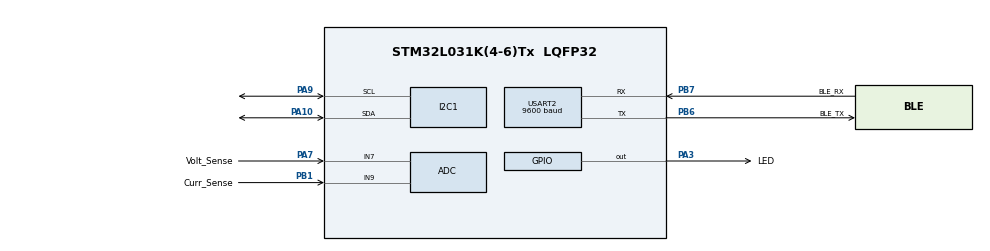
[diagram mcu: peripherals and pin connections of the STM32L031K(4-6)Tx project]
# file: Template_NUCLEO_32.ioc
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ADC.ExternalTrigConv=ADC_SOFTWARE_START
ADC.OversamplingMode=DISABLE
I2C1.Timing=0x00707CBB
Mcu.Family=STM32L0
Mcu.Name=STM32L031K(4-6)Tx
Mcu.Package=LQFP32
NVIC.TIM2_IRQn=true\:0\:0\:false\:false\:true\:true\:true
NVIC.USART2_IRQn=true\:0\:0\:false\:false\:true\:true\:true
PA10.Mode=I2C
PA10.Signal=I2C1_SDA
PA13.GPIO_Label=TMS
PA13.Mode=Serial_Wire
PA13.Signal=SYS_SWDIO
PA14.GPIO_Label=TCK
PA14.Mode=Serial_Wire
PA14.Signal=SYS_SWCLK
PA3.GPIO_Label=LED
PA3.Signal=GPIO_Output
PA7.GPIO_Label=Volt_Sense
PA7.Signal=SharedAnalog_PA7
PA9.Mode=I2C
PA9.Signal=I2C1_SCL
PB1.GPIO_Label=Curr_Sense
PB1.Signal=SharedAnalog_PB1
PB6.GPIO_Label=BLE_TX
PB6.Mode=Asynchronous
PB6.Signal=USART2_TX
PB7.GPIO_Label=BLE_RX
PB7.Mode=Asynchronous
PB7.Signal=USART2_RX
PC14-OSC32_IN.Mode=LSE-External-Oscillator
PC14-OSC32_IN.Signal=RCC_OSC32_IN
PC15-OSC32_OUT.Mode=LSE-External-Oscillator
PC15-OSC32_OUT.Signal=RCC_OSC32_OUT
ProjectManager.HeapSize=0x200
ProjectManager.StackSize=0x400
ProjectManager.TargetToolchain=MDK-ARM V5.27
RCC.AHBFreq_Value=32000000
RCC.APB1Freq_Value=32000000
RCC.APB1TimFreq_Value=32000000
RCC.APB2Freq_Value=32000000
RCC.APB2TimFreq_Value=32000000
RCC.HCLKFreq_Value=32000000
RCC.HSE_VALUE=8000000
RCC.HSI16_VALUE=16000000
RCC.HSI48_VALUE=48000000
RCC.HSI_VALUE=16000000
RCC.MSI_VALUE=2097000
RCC.PLLMUL=RCC_PLLMUL_4
RCC.SYSCLKFreq_VALUE=32000000
RCC.SYSCLKSource=RCC_SYSCLKSOURCE_PLLCLK
RCC.VCOOutputFreq_Value=64000000
SH.SharedAnalog_PA7.0=GPIO_Analog
SH.SharedAnalog_PA7.1=ADC_IN7,IN7
SH.SharedAnalog_PB1.0=GPIO_Analog
SH.SharedAnalog_PB1.1=ADC_IN9,IN9
USART2.BaudRate=9600
USART2.VirtualMode-Asynchronous=VM_ASYNC
VP_TIM2_VS_ClockSourceINT.Mode=Internal
board=NUCLEO-L031K6

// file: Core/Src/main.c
/* USER CODE BEGIN Header */
/**
  ******************************************************************************
  * @file           : main.c
  * @brief          : Main program body
  ******************************************************************************
  * @attention
  *
  * <h2><center>&copy; Copyright (c) 2021 STMicroelectronics.
  * All rights reserved.</center></h2>
  *
  * This software component is licensed by ST under BSD 3-Clause license,
  * the "License"; You may not use this file except in compliance with the
  * License. You may obtain a copy of the License at:
  *                        opensource.org/licenses/BSD-3-Clause
  *
  ******************************************************************************
  */
/* USER CODE END Header */
#include "main.h"
#include "stdio.h"
#include "string.h"
#include "hal_timer.h"
#include "hal_uart.h"

/* USER CODE BEGIN Includes */
#include "ssd1306.h"

/* USER CODE END Includes */

ADC_HandleTypeDef hadc;

I2C_HandleTypeDef hi2c1;

TIM_HandleTypeDef htim2;

UART_HandleTypeDef huart2;

uint32_t adc1, adc2;

void SystemClock_Config_ex(void);
static void MX_GPIO_Init(void);
static void MX_USART2_UART_Init(void);
static void MX_TIM2_Init(void);
static void MX_ADC_Init(void);
static void MX_I2C1_Init(void);

/* USER CODE BEGIN 0 */
uint8_t check;
uint32_t value[2];

/* USER CODE END 0 */

int main(void)
{
  /* USER CODE BEGIN 1 */
  // uint32_t raw1;
	 //uint32_t raw2;

		//char msg1[10];
	 // char msg2[10];
  /* USER CODE END 1 */

  /* MCU Configuration--------------------------------------------------------*/

  /* Reset of all peripherals, Initializes the Flash interface and the Systick. */
  HAL_Init();
	ssd1306_I2C_Init();

  /* Configure the system clock */
  SystemClock_Config_ex();

  /* Initialize all configured peripherals */
  MX_GPIO_Init();
  MX_USART2_UART_Init();
  MX_TIM2_Init();
  MX_ADC_Init();
  MX_I2C1_Init();
	SSD1306_Init();
  /* USER CODE BEGIN 2 */
	//HAL_ADCEx_Calibration_Start(&hadc, 10);

  check = SSD1306_Init();

  /* USER CODE END 2 */

  /* Infinite loop */
  while (1)
  {

    /* USER CODE BEGIN 3 */
		//&&&&&&&&&& ADC CONVERTION %%%%%%%%%%%
		//HAL_ADC_Start_DMA(&hadc,value,2);

		//hal_uart_write(value[0]);
    //HAL_Delay(25);
		//hal_uart_write(value[1]);
		//HAL_Delay(25);

		HAL_ADC_Start(&hadc);

		HAL_ADC_PollForConversion(&hadc,100);
		adc1 = HAL_ADC_GetValue(&hadc);

		HAL_ADC_PollForConversion(&hadc,100);
		adc2 = HAL_ADC_GetValue(&hadc);

		HAL_ADC_Stop(&hadc);

		HAL_Delay(100);

  }
  /* USER CODE END 3 */
}

void SystemClock_Config_ex(void)
{
  RCC_OscInitTypeDef RCC_OscInitStruct = {0};
  RCC_ClkInitTypeDef RCC_ClkInitStruct = {0};
  RCC_PeriphCLKInitTypeDef PeriphClkInit = {0};

  /** Configure the main internal regulator output voltage
  */
  __HAL_PWR_VOLTAGESCALING_CONFIG(PWR_REGULATOR_VOLTAGE_SCALE1);
  /** Initializes the RCC Oscillators according to the specified parameters
  * in the RCC_OscInitTypeDef structure.
  */
  RCC_OscInitStruct.OscillatorType = RCC_OSCILLATORTYPE_HSI;
  RCC_OscInitStruct.HSIState = RCC_HSI_ON;
  RCC_OscInitStruct.HSICalibrationValue = RCC_HSICALIBRATION_DEFAULT;
  RCC_OscInitStruct.PLL.PLLState = RCC_PLL_ON;
  RCC_OscInitStruct.PLL.PLLSource = RCC_PLLSOURCE_HSI;
  RCC_OscInitStruct.PLL.PLLMUL = RCC_PLLMUL_4;
  RCC_OscInitStruct.PLL.PLLDIV = RCC_PLLDIV_2;
  if (HAL_RCC_OscConfig(&RCC_OscInitStruct) != HAL_OK)
  {
    Error_Handler();
  }
  /** Initializes the CPU, AHB and APB buses clocks
  */
  RCC_ClkInitStruct.ClockType = RCC_CLOCKTYPE_HCLK|RCC_CLOCKTYPE_SYSCLK
                              |RCC_CLOCKTYPE_PCLK1|RCC_CLOCKTYPE_PCLK2;
  RCC_ClkInitStruct.SYSCLKSource = RCC_SYSCLKSOURCE_PLLCLK;
  RCC_ClkInitStruct.AHBCLKDivider = RCC_SYSCLK_DIV1;
  RCC_ClkInitStruct.APB1CLKDivider = RCC_HCLK_DIV1;
  RCC_ClkInitStruct.APB2CLKDivider = RCC_HCLK_DIV1;

  if (HAL_RCC_ClockConfig(&RCC_ClkInitStruct, FLASH_LATENCY_1) != HAL_OK)
  {
    Error_Handler();
  }
  PeriphClkInit.PeriphClockSelection = RCC_PERIPHCLK_USART2|RCC_PERIPHCLK_I2C1;
  PeriphClkInit.Usart2ClockSelection = RCC_USART2CLKSOURCE_PCLK1;
  PeriphClkInit.I2c1ClockSelection = RCC_I2C1CLKSOURCE_PCLK1;
  if (HAL_RCCEx_PeriphCLKConfig(&PeriphClkInit) != HAL_OK)
  {
    Error_Handler();
  }
}

static void MX_ADC_Init(void)
{

  ADC_ChannelConfTypeDef sConfig = {0};

  /** Configure the global features of the ADC (Clock, Resolution, Data Alignment and number of conversion)
  */
  hadc.Instance = ADC1;
  hadc.Init.OversamplingMode = DISABLE;
  hadc.Init.ClockPrescaler = ADC_CLOCK_SYNC_PCLK_DIV2;
  hadc.Init.Resolution = ADC_RESOLUTION_12B;
  hadc.Init.SamplingTime = ADC_SAMPLETIME_1CYCLE_5;
  hadc.Init.ScanConvMode = ADC_SCAN_DIRECTION_FORWARD;
  hadc.Init.DataAlign = ADC_DATAALIGN_RIGHT;
  hadc.Init.ContinuousConvMode = DISABLE;
  hadc.Init.DiscontinuousConvMode = DISABLE;
  hadc.Init.ExternalTrigConvEdge = ADC_EXTERNALTRIGCONVEDGE_NONE;
  hadc.Init.ExternalTrigConv = ADC_SOFTWARE_START;
  hadc.Init.DMAContinuousRequests = DISABLE;
  hadc.Init.EOCSelection = ADC_EOC_SINGLE_CONV;
  hadc.Init.Overrun = ADC_OVR_DATA_PRESERVED;
  hadc.Init.LowPowerAutoWait = DISABLE;
  hadc.Init.LowPowerFrequencyMode = DISABLE;
  hadc.Init.LowPowerAutoPowerOff = DISABLE;
  if (HAL_ADC_Init(&hadc) != HAL_OK)
  {
    Error_Handler();
  }
  /** Configure for the selected ADC regular channel to be converted.
  */
  sConfig.Channel = ADC_CHANNEL_7;
  sConfig.Rank = ADC_RANK_CHANNEL_NUMBER;
  if (HAL_ADC_ConfigChannel(&hadc, &sConfig) != HAL_OK)
  {
    Error_Handler();
  }
  /** Configure for the selected ADC regular channel to be converted.
  */
  sConfig.Channel = ADC_CHANNEL_9;
  if (HAL_ADC_ConfigChannel(&hadc, &sConfig) != HAL_OK)
  {
    Error_Handler();
  }

}

static void MX_I2C1_Init(void)
{

  hi2c1.Instance = I2C1;
  hi2c1.Init.Timing = 0x00707CBB;
  hi2c1.Init.OwnAddress1 = 0;
  hi2c1.Init.AddressingMode = I2C_ADDRESSINGMODE_7BIT;
  hi2c1.Init.DualAddressMode = I2C_DUALADDRESS_DISABLE;
  hi2c1.Init.OwnAddress2 = 0;
  hi2c1.Init.OwnAddress2Masks = I2C_OA2_NOMASK;
  hi2c1.Init.GeneralCallMode = I2C_GENERALCALL_DISABLE;
  hi2c1.Init.NoStretchMode = I2C_NOSTRETCH_DISABLE;
  if (HAL_I2C_Init(&hi2c1) != HAL_OK)
  {
    Error_Handler();
  }
  /** Configure Analogue filter
  */
  if (HAL_I2CEx_ConfigAnalogFilter(&hi2c1, I2C_ANALOGFILTER_ENABLE) != HAL_OK)
  {
    Error_Handler();
  }
  /** Configure Digital filter
  */
  if (HAL_I2CEx_ConfigDigitalFilter(&hi2c1, 0) != HAL_OK)
  {
    Error_Handler();
  }

}

static void MX_TIM2_Init(void)
{

  TIM_ClockConfigTypeDef sClockSourceConfig = {0};
  TIM_MasterConfigTypeDef sMasterConfig = {0};

  htim2.Instance = TIM2;
  htim2.Init.Prescaler = 0;
  htim2.Init.CounterMode = TIM_COUNTERMODE_UP;
  htim2.Init.Period = 65535;
  htim2.Init.ClockDivision = TIM_CLOCKDIVISION_DIV1;
  htim2.Init.AutoReloadPreload = TIM_AUTORELOAD_PRELOAD_DISABLE;
  if (HAL_TIM_Base_Init(&htim2) != HAL_OK)
  {
    Error_Handler();
  }
  sClockSourceConfig.ClockSource = TIM_CLOCKSOURCE_INTERNAL;
  if (HAL_TIM_ConfigClockSource(&htim2, &sClockSourceConfig) != HAL_OK)
  {
    Error_Handler();
  }
  sMasterConfig.MasterOutputTrigger = TIM_TRGO_RESET;
  sMasterConfig.MasterSlaveMode = TIM_MASTERSLAVEMODE_DISABLE;
  if (HAL_TIMEx_MasterConfigSynchronization(&htim2, &sMasterConfig) != HAL_OK)
  {
    Error_Handler();
  }

}

static void MX_USART2_UART_Init(void)
{

  huart2.Instance = USART2;
  huart2.Init.BaudRate = 9600;
  huart2.Init.WordLength = UART_WORDLENGTH_8B;
  huart2.Init.StopBits = UART_STOPBITS_1;
  huart2.Init.Parity = UART_PARITY_NONE;
  huart2.Init.Mode = UART_MODE_TX_RX;
  huart2.Init.HwFlowCtl = UART_HWCONTROL_NONE;
  huart2.Init.OverSampling = UART_OVERSAMPLING_16;
  huart2.Init.OneBitSampling = UART_ONE_BIT_SAMPLE_DISABLE;
  huart2.AdvancedInit.AdvFeatureInit = UART_ADVFEATURE_NO_INIT;
  if (HAL_UART_Init(&huart2) != HAL_OK)
  {
    Error_Handler();
  }

}

static void MX_GPIO_Init(void)
{
  GPIO_InitTypeDef GPIO_InitStruct = {0};

  /* GPIO Ports Clock Enable */
  __HAL_RCC_GPIOC_CLK_ENABLE();
  __HAL_RCC_GPIOA_CLK_ENABLE();
  __HAL_RCC_GPIOB_CLK_ENABLE();

  /*Configure GPIO pin Output Level */
  HAL_GPIO_WritePin(LED_GPIO_Port, LED_Pin, GPIO_PIN_RESET);

  /*Configure GPIO pin : LED_Pin */
  GPIO_InitStruct.Pin = LED_Pin;
  GPIO_InitStruct.Mode = GPIO_MODE_OUTPUT_PP;
  GPIO_InitStruct.Pull = GPIO_NOPULL;
  GPIO_InitStruct.Speed = GPIO_SPEED_FREQ_LOW;
  HAL_GPIO_Init(LED_GPIO_Port, &GPIO_InitStruct);

}

void Error_Handler(void)
{
}

/************************ (C) COPYRIGHT STMicroelectronics *****END OF FILE****/
